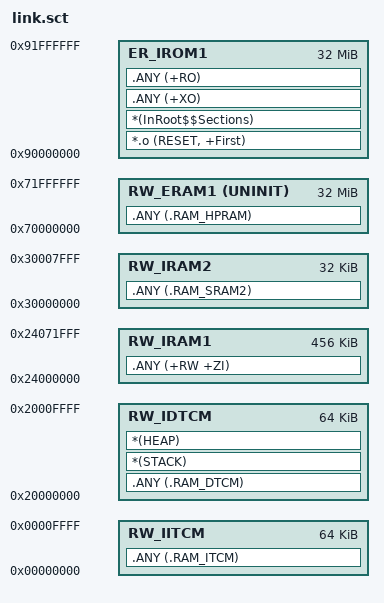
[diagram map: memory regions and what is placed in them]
LR_EROM1 0x90000000 0x02000000 {
    ER_IROM1 0x90000000 0x02000000 {	; 内部64KB的flash
        *.o (RESET, +First)
        *(InRoot$$Sections)
        .ANY (+XO)
	.ANY (+RO)
    }
    RW_IDTCM 0x20000000 0x00010000 {		; 内部DTCM，64KB不做额外映射扩展，2*32bit总线
        .ANY (.RAM_DTCM)
	*(STACK)
   	*(HEAP)
    }
	
	RW_IITCM 0x00000000 0x00010000 {		; 内部ITCM，64KB不做额外映射扩展,单64bit总线
        .ANY (.RAM_ITCM)
    }
	
	RW_IRAM1 0x24000000 0x00072000 {		; 内部AXI总线上共456KB的SRAM，四块内存统一使用，不做额外映射
        .ANY (+RW +ZI)
    }
	
	RW_IRAM2 0x30000000 0x00008000 {		; 内部AHB总线上共32KB的SRAM，两块内存统一使用
        .ANY (.RAM_SRAM2)
    }
	
	RW_ERAM1 0x70000000 UNINIT 0x02000000 {	; 外部扩展32MB的HyperBus接口的RAM
        .ANY (.RAM_HPRAM)
    }
}
